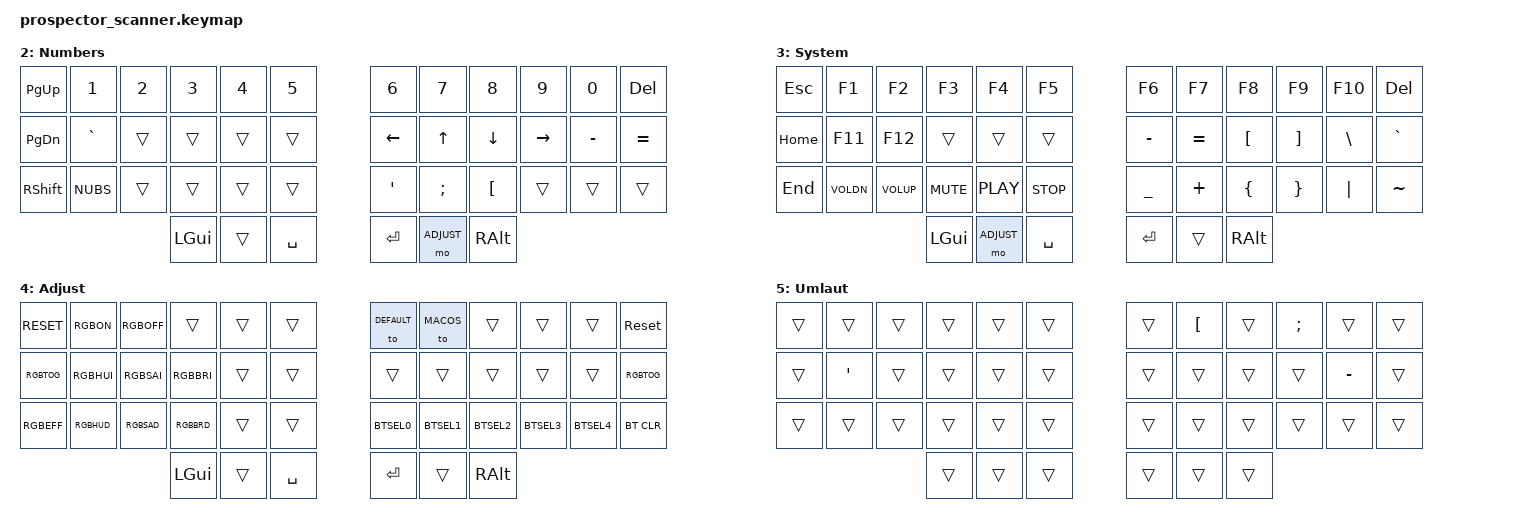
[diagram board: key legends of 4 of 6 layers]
// Basic import
#include <behaviors.dtsi>
#include <dt-bindings/zmk/keys.h>
#include <dt-bindings/zmk/bt.h>
#include <dt-bindings/zmk/outputs.h>

// Layers
#define DEFAULT 0
#define MACOS   1
#define NUMBER  2
#define SYSCTL  3
#define ADJUST  4
#define UMLAUT  5

/ {
    keymap {
        compatible = "zmk,keymap";

                // ── Layer 0: DEFAULT ─────────────────────────────────────────
                default_layer {
                    display-name = "Base";
                        bindings = <
// ╭─────────────────────────────────────────────────────────────────╮   ╭─────────────────────────────────────────────────────────────────╮
// │   ESC    │    Q     │    W     │    E     │    R     │    T     │   │    Y     │    U     │    I     │    O     │    P     │   BKSP   │
    &kp ESC    QQUIT      &kp W      &kp E      &kp R      TTAB          YREDO      &kp U      &kp I      OOPEN      PPRINT     &kp BSPC
// ├──────────┼──────────┼──────────┼──────────┼──────────┼──────────┤   ├──────────┼──────────┼──────────┼──────────┼──────────┼──────────┤
// │   TAB    │    A     │    S     │    D     │    F     │    G     │   │    H     │    J     │    K     │    L     │    ]     │   NUHS   │
    &kp TAB    AALL       SSAVE      &kp D      FFIND      &kp G          &kp H      &kp J      &kp K      &kp L      &kp RBKT   &kp NUHS
// ├──────────┼──────────┼──────────┼──────────┼──────────┼──────────┤   ├──────────┼──────────┼──────────┼──────────┼──────────┼──────────┤
// │ LSHIFT   │    Z     │    X     │    C     │    V     │    B     │   │    N     │    M     │    ,     │    .     │    /     │   RCTRL  │
    &shift_td3 ZUNDO      XCUT       CCOPY      VPASTE     &kp B          NNEW       &kp M      &kp COMMA  &kp DOT    &kp FSLH   &kp RCTRL
// ╰──────────┼──────────┼──────────┼──────────┼──────────┼──────────┤   ├──────────┼──────────┼──────────┼──────────┼──────────┼──────────╯
//                                  │   LGUI   │   LWR    │   SPACE  │   │  ENTER   │   RSE    │  RALT    │
                                     &win_td3   &mo NUMBER &kp SPACE      &kp ENTER  &mo SYSCTL &kp RALT
//                                  ╰────────────────────────────────╯   ╰────────────────────────────────╯
                        >;
                };

                                // ── Layer 1: MacOS ──────────────────────────────────────────
                macos_layer {
                    display-name = "MacOS";
                        bindings = <
// ╭─────────────────────────────────────────────────────────────────╮   ╭─────────────────────────────────────────────────────────────────╮
// │   ESC    │    Q     │    W     │    E     │    R     │    T     │   │    Y     │    U     │    I     │    O     │    P     │   BKSP   │
    &kp ESC    QQUIT_M    &kp W      &kp E      &kp R      TTAB_M         YREDO_M    &kp U      &kp I      OOPEN_M    PPRINT_M   &kp BSPC
// ├──────────┼──────────┼──────────┼──────────┼──────────┼──────────┤   ├──────────┼──────────┼──────────┼──────────┼──────────┼──────────┤
// │   TAB    │    A     │    S     │    D     │    F     │    G     │   │    H     │    J     │    K     │    L     │    ]     │   NUHS   │
    &kp TAB    AALL_M     SSAVE_M    &kp D      FFIND_M    &kp G          &kp H      &kp J      &kp K      &kp L      &kp RBKT   &kp NUHS
// ├──────────┼──────────┼──────────┼──────────┼──────────┼──────────┤   ├──────────┼──────────┼──────────┼──────────┼──────────┼──────────┤
// │ LSHIFT   │    Z     │    X     │    C     │    V     │    B     │   │    N     │    M     │    ,     │    .     │    /     │   RCTRL  │
    &shift_td3 ZUNDO_M    XCUT_M     CCOPY_M    VPASTE_M   &kp B          NNEW_M     &kp M      &kp COMMA  &kp DOT    &kp FSLH   &kp RCTRL
// ╰──────────┼──────────┼──────────┼──────────┼──────────┼──────────┤   ├──────────┼──────────┼──────────┼──────────┼──────────┼──────────╯
//                                  │  L-OPT   │   LWR    │   SPACE  │   │  ENTER   │   RSE    │  CMD    │
                                     &kp LALT   &mo NUMBER &kp SPACE      &kp ENTER  &mo SYSCTL &kp LGUI
//                                  ╰────────────────────────────────╯   ╰────────────────────────────────╯
                        >;
                };

                // ── Layer 3: NUMBER ──────────────────────────────────────────
                number_layer {
                    display-name = "Numbers";
                        bindings = <
// ╭─────────────────────────────────────────────────────────────────╮   ╭─────────────────────────────────────────────────────────────────╮
// │   PGUP   │    1     │    2     │    3     │    4     │    5     │   │    6     │    7     │    8     │    9     │    0     │    DEL   │
    &kp PG_UP  &kp N1     &kp N2     &kp N3     &kp N4     &kp N5          &kp N6     &kp N7     &kp N8     &kp N9     &kp N0     &kp DEL
// ├──────────┼──────────┼──────────┼──────────┼──────────┼──────────┤   ├──────────┼──────────┼──────────┼──────────┼──────────┼──────────┤
// │   PGDN   │    `     │          │          │          │          │   │   LEFT   │    UP    │   DOWN   │  RIGHT   │    -     │    =     │
    &kp PG_DN  &kp GRAVE  &trans     &trans     &trans     &trans         &kp LEFT   &kp UP     &kp DOWN   &kp RIGHT  &kp MINUS  &kp EQUAL
// ├──────────┼──────────┼──────────┼──────────┼──────────┼──────────┤   ├──────────┼──────────┼──────────┼──────────┼──────────┼──────────┤
// │ RSHIFT   │   NUBS   │          │          │          │          │   │   "'"    │    ;     │    [     │          │          │          │
    &kp RSHFT  &kp NUBS   &trans     &trans     &trans     &trans          &kp APOS   &kp SEMI   &kp LBKT  &trans     &trans     &trans
// ╰──────────┼──────────┼──────────┼──────────┼──────────┼──────────┤   ├──────────┼──────────┼──────────┼──────────┼──────────┼──────────╯
//                                  │   LGUI   │   ADJ    │  SPACE   │   │   ENTER  │   ADJ    │  RALT    │
                                     &kp LGUI   &trans     &kp SPACE      &kp ENTER  &mo ADJUST &kp RALT
//                                  ╰────────────────────────────────╯   ╰────────────────────────────────╯
                        >;
                };

                // ── Layer 4: SYSCTL ──────────────────────────────────────────
                sysctl_layer {
                    display-name = "System";
                        bindings = <
// ╭─────────────────────────────────────────────────────────────────╮   ╭─────────────────────────────────────────────────────────────────╮
// │   ESC    │    F1    │    F2    │    F3    │    F4    │    F5    │   │    F6    │    F7    │    F8    │    F9    │   F10    │    DEL   │
    &kp ESC    &kp F1     &kp F2     &kp F3     &kp F4     &kp F5         &kp F6     &kp F7     &kp F8     &kp F9     &kp F10    &kp DEL
// ├──────────┼──────────┼──────────┼──────────┼──────────┼──────────┤   ├──────────┼──────────┼──────────┼──────────┼──────────┼──────────┤
// │   HOME   │   F11    │   F12    │          │          │          │   │    -     │    =     │    [     │    ]     │    \     │    `     │
    &kp HOME   &kp F11    &kp F12    &trans     &trans     &trans         &kp MINUS  &kp EQUAL  &kp LBKT   &kp RBKT   &kp BSLH   &kp GRAVE
// ├──────────┼──────────┼──────────┼──────────┼──────────┼──────────┤   ├──────────┼──────────┼──────────┼──────────┼──────────┼──────────┤
// │   END    │  VOL-    │  VOL+    │  MUTE    │  PLAY    │  MSTP    │   │    _     │    +     │    {     │    }     │    |     │    ~     │
    &kp END    VOLDN      VOLUP      &kp C_MUTE &kp C_PLAY &kp C_STOP     &kp UNDER  &kp PLUS   &kp LBRC   &kp RBRC   &kp PIPE   &kp TILDE
// ╰──────────┼──────────┼──────────┼──────────┼──────────┼──────────┤   ├──────────┼──────────┼──────────┼──────────┼──────────┼──────────╯
//                                  │   LGUI   │   ADJ    │  SPACE   │   │  ENTER   │   ADJ    │   RALT   │
                                     &kp LGUI   &mo ADJUST &kp SPACE       &kp ENTER &trans     &kp RALT
//                                  ╰────────────────────────────────╯   ╰────────────────────────────────╯
                        >;
                };

                // ── Layer 5: ADJUST ──────────────────────────────────────────
                adjust_layer {
                    display-name = "Adjust";
                        bindings = <
// ╭─────────────────────────────────────────────────────────────────╮   ╭─────────────────────────────────────────────────────────────────╮
// │   RESET  │  RGB_ON  │ RGB_OFF  │          │          │          │   │→ DEFAULT │→ MAC     │          │          │          │ SysReset │
    RESET      RGBON      RGBOFF     &trans     &trans     &trans         &to DEFAULT &to MACOS &trans     &trans     &trans     &sys_reset
// ├──────────┼──────────┼──────────┼──────────┼──────────┼──────────┤   ├──────────┼──────────┼──────────┼──────────┼──────────┼──────────┤
// │ RGB_TOG  │ RGB_HUI  │ RGB_SAI  │ RGB_BRI  │          │          │   │          │          │          │          │          │ RGB_TOG  │
    RGBTOG     RGBHUI     RGBSAI     RGBBRI     &trans     &trans         &trans     &trans     &trans     &trans     &trans     RGBTOG
// ├──────────┼──────────┼──────────┼──────────┼──────────┼──────────┤   ├──────────┼──────────┼──────────┼──────────┼──────────┼──────────┤
// │ RGB_EFF  │ RGB_HUD  │ RGB_SAD  │ RGB_BRD  │          │          │   │    BT1   │    BT2   │    BT3   │    BT4   │    BT5   │ BTReset  │
    RGBEFF     RGBHUD     RGBSAD     RGBBRD     &trans     &trans         BTSEL0     BTSEL1     BTSEL2     BTSEL3     BTSEL4     &bt BT_CLR
// ╰──────────┼──────────┼──────────┼──────────┼──────────┼──────────┤   ├──────────┼──────────┼──────────┼──────────┼──────────┼──────────╯
//                                  │   LGUI   │   ADJ    │  SPACE   │   │  ENTER   │    ADJ   │   RALT   │
                                     &kp LGUI   &trans     &kp SPACE      &kp ENTER  &trans     &kp RALT
//                                  ╰────────────────────────────────╯   ╰────────────────────────────────╯
                        >;
                };

                // ── Layer 6: UMLAUT ──────────────────────────────────────────
                umlaut_layer {
                    display-name = "Umlaut";
                        bindings = <
// ╭─────────────────────────────────────────────────────────────────╮   ╭─────────────────────────────────────────────────────────────────╮
// │          │          │          │          │          │          │   │          │    ü     │          │    Ö     │          │          │
    &trans     &trans     &trans     &trans     &trans     &trans         &trans     &kp LBKT   &trans     &kp SEMI   &trans     &trans
// ├──────────┼──────────┼──────────┼──────────┼──────────┼──────────┤   ├──────────┼──────────┼──────────┼──────────┼──────────┼──────────┤
// │          │    Ä     │          │          │          │          │   │          │          │          │          │    ß     │          │
    &trans     &kp APOS   &trans     &trans     &trans     &trans         &trans     &trans     &trans     &trans     &kp MINUS  &trans
// ├──────────┼──────────┼──────────┼──────────┼──────────┼──────────┤   ├──────────┼──────────┼──────────┼──────────┼──────────┼──────────┤
// │          │          │          │          │          │          │   │          │          │          │          │          │          │
    &trans     &trans     &trans     &trans     &trans     &trans         &trans     &trans     &trans     &trans     &trans     &trans
// ╰──────────┼──────────┼──────────┼──────────┼──────────┼──────────┤   ├──────────┼──────────┼──────────┼──────────┼──────────┼──────────╯
//                                  │          │          │          │   │          │          │  [RALT]  │
                                     &trans     &trans     &trans         &trans     &trans     &trans
//                                  ╰────────────────────────────────╯   ╰────────────────────────────────╯
                        >;
                };
        };
};
